AUTOSAR XML (schema 4-0-3)
standard types defined: Boolean, UInt8
package /AUTOSAR_Platform/DataConstrs
  range DC_Boolean: raw 0..1
package /PATAC/MSM/ComponentTypes
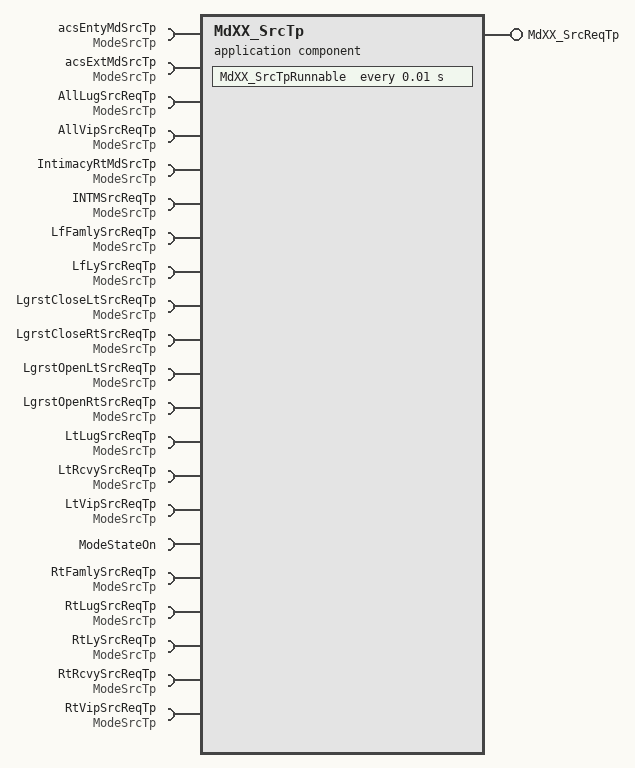
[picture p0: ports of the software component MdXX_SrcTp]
  application sw component type MdXX_SrcTp
    provide port MdXX_SrcReqTp: provided-interface=MdXX_SrcReqTp
      provided-com-specs:
        data-element=Md1_SrcTp, init-value=0
        data-element=Md{10..19}_SrcTp, init-value=0
        data-element=Md2_SrcTp, init-value=0
        data-element=Md{20..29}_SrcTp, init-value=0
        data-element=Md3_SrcTp, init-value=0
        data-element=Md{30..32}_SrcTp, init-value=0
        data-element=Md{4..9}_SrcTp, init-value=0
    21 x require port:
      acsEntyMdSrcTp: nonqueued-receiver-com-spec{data-element=ModeSrcTp/Val, filter=data-filter-type=ALWAYS, init-value=0}, required-interface=ModeSrcTp
      acsExtMdSrcTp: nonqueued-receiver-com-spec{data-element=ModeSrcTp/Val, filter=data-filter-type=ALWAYS, init-value=0}, required-interface=ModeSrcTp
      AllLugSrcReqTp: nonqueued-receiver-com-spec{data-element=ModeSrcTp/Val, filter=data-filter-type=ALWAYS, init-value=0}, required-interface=ModeSrcTp
      AllVipSrcReqTp: nonqueued-receiver-com-spec{data-element=ModeSrcTp/Val, filter=data-filter-type=ALWAYS, init-value=0}, required-interface=ModeSrcTp
      IntimacyRtMdSrcTp: nonqueued-receiver-com-spec{data-element=ModeSrcTp/Val, filter=data-filter-type=ALWAYS, init-value=0}, required-interface=ModeSrcTp
      INTMSrcReqTp: nonqueued-receiver-com-spec{data-element=ModeSrcTp/Val, filter=data-filter-type=ALWAYS, init-value=0}, required-interface=ModeSrcTp
      LfFamlySrcReqTp: nonqueued-receiver-com-spec{data-element=ModeSrcTp/Val, filter=data-filter-type=ALWAYS, init-value=0}, required-interface=ModeSrcTp
      LfLySrcReqTp: nonqueued-receiver-com-spec{data-element=ModeSrcTp/Val, filter=data-filter-type=ALWAYS, init-value=0}, required-interface=ModeSrcTp
      LgrstCloseLtSrcReqTp: nonqueued-receiver-com-spec{data-element=ModeSrcTp/Val, filter=data-filter-type=ALWAYS, init-value=0}, required-interface=ModeSrcTp
      LgrstCloseRtSrcReqTp: nonqueued-receiver-com-spec{data-element=ModeSrcTp/Val, filter=data-filter-type=ALWAYS, init-value=0}, required-interface=ModeSrcTp
      LgrstOpenLtSrcReqTp: nonqueued-receiver-com-spec{data-element=ModeSrcTp/Val, filter=data-filter-type=ALWAYS, init-value=0}, required-interface=ModeSrcTp
      LgrstOpenRtSrcReqTp: nonqueued-receiver-com-spec{data-element=ModeSrcTp/Val, filter=data-filter-type=ALWAYS, init-value=0}, required-interface=ModeSrcTp
      LtLugSrcReqTp: nonqueued-receiver-com-spec{data-element=ModeSrcTp/Val, filter=data-filter-type=ALWAYS, init-value=0}, required-interface=ModeSrcTp
      LtRcvySrcReqTp: nonqueued-receiver-com-spec{data-element=ModeSrcTp/Val, filter=data-filter-type=ALWAYS, init-value=0}, required-interface=ModeSrcTp
      LtVipSrcReqTp: nonqueued-receiver-com-spec{data-element=ModeSrcTp/Val, filter=data-filter-type=ALWAYS, init-value=0}, required-interface=ModeSrcTp
      ModeStateOn: nonqueued-receiver-com-spec{data-element=ModeStateOn/Val, filter=data-filter-type=ALWAYS, init-value=0}, required-interface=ModeStateOn
      RtFamlySrcReqTp: nonqueued-receiver-com-spec{data-element=ModeSrcTp/Val, filter=data-filter-type=ALWAYS, init-value=0}, required-interface=ModeSrcTp
      RtLugSrcReqTp: nonqueued-receiver-com-spec{data-element=ModeSrcTp/Val, filter=data-filter-type=ALWAYS, init-value=0}, required-interface=ModeSrcTp
      RtLySrcReqTp: nonqueued-receiver-com-spec{data-element=ModeSrcTp/Val, filter=data-filter-type=ALWAYS, init-value=0}, required-interface=ModeSrcTp
      RtRcvySrcReqTp: nonqueued-receiver-com-spec{data-element=ModeSrcTp/Val, filter=data-filter-type=ALWAYS, init-value=0}, required-interface=ModeSrcTp
      RtVipSrcReqTp: nonqueued-receiver-com-spec{data-element=ModeSrcTp/Val, filter=data-filter-type=ALWAYS, init-value=0}, required-interface=ModeSrcTp
    behavior MdXX_SrcTp_InternalBehavior
      timing event TMT_MdXX_SrcTpRunnable: start-on-event=MdXX_SrcTpRunnable, period=0.01
      runnable MdXX_SrcTpRunnable
        data-receive-point-by-arguments:
          21 x access:
            REC_acsEntyMdSrcTp_Val: accessed-variable=acsEntyMdSrcTp.Val
            REC_acsExtMdSrcTp_Val: accessed-variable=acsExtMdSrcTp.Val
            REC_AllLugSrcReqTp_Val: accessed-variable=AllLugSrcReqTp.Val
            REC_AllVipSrcReqTp_Val: accessed-variable=AllVipSrcReqTp.Val
            REC_IntimacyRtMdSrcTp_Val: accessed-variable=IntimacyRtMdSrcTp.Val
            REC_INTMSrcReqTp_Val: accessed-variable=INTMSrcReqTp.Val
            REC_LfFamlySrcReqTp_Val: accessed-variable=LfFamlySrcReqTp.Val
            REC_LfLySrcReqTp_Val: accessed-variable=LfLySrcReqTp.Val
            REC_LgrstCloseLtSrcReqTp_Val: accessed-variable=LgrstCloseLtSrcReqTp.Val
            REC_LgrstCloseRtSrcReqTp_Val: accessed-variable=LgrstCloseRtSrcReqTp.Val
            REC_LgrstOpenLtSrcReqTp_Val: accessed-variable=LgrstOpenLtSrcReqTp.Val
            REC_LgrstOpenRtSrcReqTp_Val: accessed-variable=LgrstOpenRtSrcReqTp.Val
            REC_LtLugSrcReqTp_Val: accessed-variable=LtLugSrcReqTp.Val
            REC_LtRcvySrcReqTp_Val: accessed-variable=LtRcvySrcReqTp.Val
            REC_LtVipSrcReqTp_Val: accessed-variable=LtVipSrcReqTp.Val
            REC_ModeStateOn_Val: accessed-variable=ModeStateOn.Val
            REC_RtFamlySrcReqTp_Val: accessed-variable=RtFamlySrcReqTp.Val
            REC_RtLugSrcReqTp_Val: accessed-variable=RtLugSrcReqTp.Val
            REC_RtLySrcReqTp_Val: accessed-variable=RtLySrcReqTp.Val
            REC_RtRcvySrcReqTp_Val: accessed-variable=RtRcvySrcReqTp.Val
            REC_RtVipSrcReqTp_Val: accessed-variable=RtVipSrcReqTp.Val
        data-send-points:
          32 x access:
            SEND_MdXX_SrcReqTp_Md1_SrcTp: accessed-variable=MdXX_SrcReqTp.Md1_SrcTp
            SEND_MdXX_SrcReqTp_Md{10..19}_SrcTp: accessed-variable=MdXX_SrcReqTp.Md{10..19}_SrcTp
            SEND_MdXX_SrcReqTp_Md2_SrcTp: accessed-variable=MdXX_SrcReqTp.Md2_SrcTp
            SEND_MdXX_SrcReqTp_Md{20..29}_SrcTp: accessed-variable=MdXX_SrcReqTp.Md{20..29}_SrcTp
            SEND_MdXX_SrcReqTp_Md3_SrcTp: accessed-variable=MdXX_SrcReqTp.Md3_SrcTp
            SEND_MdXX_SrcReqTp_Md{30..32}_SrcTp: accessed-variable=MdXX_SrcReqTp.Md{30..32}_SrcTp
            SEND_MdXX_SrcReqTp_Md{4..9}_SrcTp: accessed-variable=MdXX_SrcReqTp.Md{4..9}_SrcTp
  swc implementation MdXX_SrcTp_Implementation: behavior=MdXX_SrcTp_InternalBehavior
    code-descriptors:
      code Default: artifact-descriptors=autosar-engineering-object={short-label=Default, category=SWSRC}
package /PATAC/MSM/ModeAdjust/DataType
  impl type SrcReqTp1: category=VALUE, base-type=UInt8, sw-calibration-access=READ-ONLY, compu {0=SrcReqTp_None, 1=SrcReqTp_Local, 2=SrcReqTp_HMI2L, 3=SrcReqTp_HMI2R, 4=SrcReqTp_HMI, 5=SrcReqTp_Remote, 6=SrcReqTp_SRS}, type-emitter=RTE
package /PATAC/MSM/ModeAdjust/PortInterface
  sender receiver interface MdXX_SrcReqTp
    32 x data, all with type=SrcReqTp1:
      Md1_SrcTp
      Md{10..19}_SrcTp
      Md2_SrcTp
      Md{20..29}_SrcTp
      Md3_SrcTp
      Md{30..32}_SrcTp
      Md{4..9}_SrcTp
    invalidation-policys:
      data-element=Md1_SrcTp, handle-invalid=DONT-INVALIDATE
      data-element=Md2_SrcTp, handle-invalid=DONT-INVALIDATE
      data-element=Md4_SrcTp, handle-invalid=DONT-INVALIDATE
      data-element=Md3_SrcTp, handle-invalid=DONT-INVALIDATE
      data-element=Md6_SrcTp, handle-invalid=DONT-INVALIDATE
      data-element=Md5_SrcTp, handle-invalid=DONT-INVALIDATE
      data-element=Md10_SrcTp, handle-invalid=DONT-INVALIDATE
      data-element=Md7_SrcTp, handle-invalid=DONT-INVALIDATE
      data-element=Md12_SrcTp, handle-invalid=DONT-INVALIDATE
      data-element=Md8_SrcTp, handle-invalid=DONT-INVALIDATE
      data-element=Md11_SrcTp, handle-invalid=DONT-INVALIDATE
      data-element=Md9_SrcTp, handle-invalid=DONT-INVALIDATE
      data-element=Md14_SrcTp, handle-invalid=DONT-INVALIDATE
      data-element=Md13_SrcTp, handle-invalid=DONT-INVALIDATE
      data-element=Md17_SrcTp, handle-invalid=DONT-INVALIDATE
      data-element=Md16_SrcTp, handle-invalid=DONT-INVALIDATE
      data-element=Md15_SrcTp, handle-invalid=DONT-INVALIDATE
      data-element=Md19_SrcTp, handle-invalid=DONT-INVALIDATE
      data-element=Md18_SrcTp, handle-invalid=DONT-INVALIDATE
      data-element=Md{20..22}_SrcTp, handle-invalid=DONT-INVALIDATE
      data-element=Md24_SrcTp, handle-invalid=DONT-INVALIDATE
      data-element=Md23_SrcTp, handle-invalid=DONT-INVALIDATE
      data-element=Md26_SrcTp, handle-invalid=DONT-INVALIDATE
      data-element=Md25_SrcTp, handle-invalid=DONT-INVALIDATE
      data-element=Md28_SrcTp, handle-invalid=DONT-INVALIDATE
      data-element=Md27_SrcTp, handle-invalid=DONT-INVALIDATE
      data-element=Md30_SrcTp, handle-invalid=DONT-INVALIDATE
      data-element=Md29_SrcTp, handle-invalid=DONT-INVALIDATE
      data-element=Md32_SrcTp, handle-invalid=DONT-INVALIDATE
      data-element=Md31_SrcTp, handle-invalid=DONT-INVALIDATE
  sender receiver interface ModeSrcTp: invalidation-policy{data-element=ModeSrcTp/Val, handle-invalid=DONT-INVALIDATE}
    data Val: type=SrcReqTp1
  sender receiver interface ModeStateOn: invalidation-policy{data-element=ModeStateOn/Val, handle-invalid=DONT-INVALIDATE}
    data Val: type=Boolean
